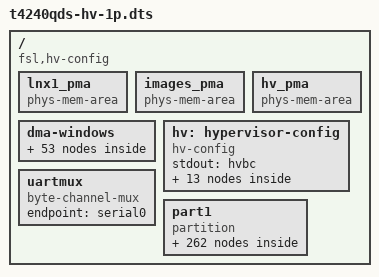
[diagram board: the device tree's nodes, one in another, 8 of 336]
/* Hypervisor Configuration tree containing all hypervisor configuration
 * parameters and partition definition information.
 * (Note -- Please refer to Hypervisor SW Reference Manual
 * (Chapter 5 Configuration) for further details)
 *
 * Copyright 2014 Freescale Semiconductor, Inc.
 */

/dts-v1/;

/ {	// root node

	// The root node of the configuration device tree must contain a
	// compatible property that identifies the device tree as a hypervisor

	compatible = "fsl,hv-config";

	// =====================================================
	// Physical Memory Areas
	// =====================================================
	lnx1_pma: lnx1_pma {
		compatible = "phys-mem-area";
		addr = <0x0 0x00000000>;	// Linux
		size = <0x0 0x40000000>;	// 1GB
	};


	images_pma: images_pma {
		compatible = "phys-mem-area";
		addr = <0x0 0x78000000>;	// Used for boot-from-RAM
		size = <0x0 0x04000000>;	// 64MB
	};

	hv_pma: hv_pma {
		compatible = "phys-mem-area";
		addr = <0x0 0x7f000000>;	// Hypervisor
		size = <0x0 0x01000000>;	// 16MB
	};

	// =====================================================
	// DMA Windows
	// =====================================================
	dma-windows {
		// DMA window for part1_linux
		dw_linux1: dw_linux1 {
			compatible = "dma-window";
			guest-addr = <0 0>;
			size = <0x0 0x80000000>; // 2GB
			subwindow-count = <2>;

			sub-window@0 {
				compatible = "dma-subwindow";
				guest-addr = <0 0>;
				size = <0 0x40000000>; // 1GB
			};

			// ====================================================
			// The window is used for MSIIR translation. The
			// hypervisor sets  a property in the guest device tree
			// (msi-address-64) which indicates the guest physical
			// address of the MSIIR register.
			// This address must be in the next page after the end
			// of DDR as seen by the guest. This is because, Linux
			// is extending the DDR ATMU with one page in order to
			// cover the MSIIR register.
			// ====================================================
			sub-window@1 {		// MSI sub-window
				compatible = "dma-subwindow";
				guest-addr = <0 0x40000000>;
				size = <0 0x1000>; // 4KB
				pcie-msi-subwindow;
			};

		};

		// DMA window for stash_dqrr for qman-portal0
		dw_dqrr_qportal0: window3 {
			compatible = "dma-window";
			guest-addr = <0xf 0xf6000000>;
			size = <0 0x4000>;
		};

		// DMA window for stash_dqrr for qman-portal1
		dw_dqrr_qportal1: window4 {
			compatible = "dma-window";
			guest-addr = <0xf 0xf6004000>;
			size = <0 0x4000>;
		};

		// DMA window for stash_dqrr for qman-portal2
		dw_dqrr_qportal2: window5 {
			compatible = "dma-window";
			guest-addr = <0xf 0xf6008000>;
			size = <0 0x4000>;
		};

		// DMA window for stash_dqrr for qman-portal3
		dw_dqrr_qportal3: window6 {
			compatible = "dma-window";
			guest-addr = <0xf 0xf600c000>;
			size = <0 0x4000>;
		};

		// DMA window for stash_dqrr for qman-portal4
		dw_dqrr_qportal4: window7 {
			compatible = "dma-window";
			guest-addr = <0xf 0xf6010000>;
			size = <0 0x4000>;
		};

		// DMA window for stash_dqrr for qman-portal5
		dw_dqrr_qportal5: window8 {
			compatible = "dma-window";
			guest-addr = <0xf 0xf6014000>;
			size = <0 0x4000>;
		};

		// DMA window for stash_dqrr for qman-portal6
		dw_dqrr_qportal6: window9 {
			compatible = "dma-window";
			guest-addr = <0xf 0xf6018000>;
			size = <0 0x4000>;
		};

		// DMA window for stash_dqrr for qman-portal7
		dw_dqrr_qportal7: window10 {
			compatible = "dma-window";
			guest-addr = <0xf 0xf601c000>;
			size = <0 0x4000>;
		};

		// DMA window for stash_dqrr for qman-portal8
		dw_dqrr_qportal8: window11 {
			compatible = "dma-window";
			guest-addr = <0xf 0xf6020000>;
			size = <0 0x4000>;
		};

		// DMA window for stash_dqrr for qman-portal9
		dw_dqrr_qportal9: window12 {
			compatible = "dma-window";
			guest-addr = <0xf 0xf6024000>;
			size = <0 0x4000>;
		};

		// DMA window for stash_dqrr for qman-portal10
		dw_dqrr_qportal10: window13 {
			compatible = "dma-window";
			guest-addr = <0xf 0xf6028000>;
			size = <0 0x4000>;
		};

		// DMA window for stash_dqrr for qman-portal11
		dw_dqrr_qportal11: window14 {
			compatible = "dma-window";
			guest-addr = <0xf 0xf602c000>;
			size = <0 0x4000>;
		};

		// DMA window for stash_dqrr for qman-portal12
		dw_dqrr_qportal12: window15 {
			compatible = "dma-window";
			guest-addr = <0xf 0xf6030000>;
			size = <0 0x4000>;
		};

		// DMA window for stash_dqrr for qman-portal13
		dw_dqrr_qportal13: window16 {
			compatible = "dma-window";
			guest-addr = <0xf 0xf6034000>;
			size = <0 0x4000>;
		};

		// DMA window for stash_dqrr for qman-portal14
		dw_dqrr_qportal14: window17 {
			compatible = "dma-window";
			guest-addr = <0xf 0xf6038000>;
			size = <0 0x4000>;
		};

		// DMA window for stash_dqrr for qman-portal15
		dw_dqrr_qportal15: window18 {
			compatible = "dma-window";
			guest-addr = <0xf 0xf603c000>;
			size = <0 0x4000>;
		};

		// DMA window for stash_dqrr for qman-portal16
		dw_dqrr_qportal16: window19 {
			compatible = "dma-window";
			guest-addr = <0xf 0xf6040000>;
			size = <0 0x4000>;
		};

		// DMA window for stash_dqrr for qman-portal17
		dw_dqrr_qportal17: window20 {
			compatible = "dma-window";
			guest-addr = <0xf 0xf6044000>;
			size = <0 0x4000>;
		};

		// DMA window for stash_dqrr for qman-portal18
		dw_dqrr_qportal18: window21 {
			compatible = "dma-window";
			guest-addr = <0xf 0xf6048000>;
			size = <0 0x4000>;
		};

		// DMA window for stash_dqrr for qman-portal19
		dw_dqrr_qportal19: window22 {
			compatible = "dma-window";
			guest-addr = <0xf 0xf604c000>;
			size = <0 0x4000>;
		};

		// DMA window for stash_dqrr for qman-portal20
		dw_dqrr_qportal20: window23 {
			compatible = "dma-window";
			guest-addr = <0xf 0xf6050000>;
			size = <0 0x4000>;
		};

		// DMA window for stash_dqrr for qman-portal21
		dw_dqrr_qportal21: window24 {
			compatible = "dma-window";
			guest-addr = <0xf 0xf6054000>;
			size = <0 0x4000>;
		};

		// DMA window for stash_dqrr for qman-portal22
		dw_dqrr_qportal22: window25 {
			compatible = "dma-window";
			guest-addr = <0xf 0xf6058000>;
			size = <0 0x4000>;
		};

		// DMA window for stash_dqrr for qman-portal23
		dw_dqrr_qportal23: window26 {
			compatible = "dma-window";
			guest-addr = <0xf 0xf605c000>;
			size = <0 0x4000>;
		};

		// DMA window for stash_dqrr for qman-portal24
		dw_dqrr_qportal24: window27 {
			compatible = "dma-window";
			guest-addr = <0xf 0xf6060000>;
			size = <0 0x4000>;
		};

		// DMA window for stash_dqrr for qman-portal25
		dw_dqrr_qportal25: window28 {
			compatible = "dma-window";
			guest-addr = <0xf 0xf6064000>;
			size = <0 0x4000>;
		};

		// DMA window for stash_dqrr for qman-portal26
		dw_dqrr_qportal26: window29 {
			compatible = "dma-window";
			guest-addr = <0xf 0xf6068000>;
			size = <0 0x4000>;
		};

		// DMA window for stash_dqrr for qman-portal27
		dw_dqrr_qportal27: window30 {
			compatible = "dma-window";
			guest-addr = <0xf 0xf606c000>;
			size = <0 0x4000>;
		};

		// DMA window for stash_dqrr for qman-portal28
		dw_dqrr_qportal28: window31 {
			compatible = "dma-window";
			guest-addr = <0xf 0xf6070000>;
			size = <0 0x4000>;
		};

		// DMA window for stash_dqrr for qman-portal29
		dw_dqrr_qportal29: window32 {
			compatible = "dma-window";
			guest-addr = <0xf 0xf6074000>;
			size = <0 0x4000>;
		};

		// DMA window for stash_dqrr for qman-portal30
		dw_dqrr_qportal30: window33 {
			compatible = "dma-window";
			guest-addr = <0xf 0xf6078000>;
			size = <0 0x4000>;
		};

		// DMA window for stash_dqrr for qman-portal31
		dw_dqrr_qportal31: window34 {
			compatible = "dma-window";
			guest-addr = <0xf 0xf607c000>;
			size = <0 0x4000>;
		};

		// DMA window for stash_dqrr for qman-portal32
		dw_dqrr_qportal32: window35 {
			compatible = "dma-window";
			guest-addr = <0xf 0xf6080000>;
			size = <0 0x4000>;
		};

		// DMA window for stash_dqrr for qman-portal33
		dw_dqrr_qportal33: window36 {
			compatible = "dma-window";
			guest-addr = <0xf 0xf6084000>;
			size = <0 0x4000>;
		};

		// DMA window for stash_dqrr for qman-portal34
		dw_dqrr_qportal34: window37 {
			compatible = "dma-window";
			guest-addr = <0xf 0xf6088000>;
			size = <0 0x4000>;
		};

		// DMA window for stash_dqrr for qman-portal35
		dw_dqrr_qportal35: window38 {
			compatible = "dma-window";
			guest-addr = <0xf 0xf608c000>;
			size = <0 0x4000>;
		};

		// DMA window for stash_dqrr for qman-portal36
		dw_dqrr_qportal36: window39 {
			compatible = "dma-window";
			guest-addr = <0xf 0xf6090000>;
			size = <0 0x4000>;
		};

		// DMA window for stash_dqrr for qman-portal37
		dw_dqrr_qportal37: window40 {
			compatible = "dma-window";
			guest-addr = <0xf 0xf6094000>;
			size = <0 0x4000>;
		};

		// DMA window for stash_dqrr for qman-portal38
		dw_dqrr_qportal38: window41 {
			compatible = "dma-window";
			guest-addr = <0xf 0xf6098000>;
			size = <0 0x4000>;
		};

		// DMA window for stash_dqrr for qman-portal39
		dw_dqrr_qportal39: window42 {
			compatible = "dma-window";
			guest-addr = <0xf 0xf609c000>;
			size = <0 0x4000>;
		};

		// DMA window for stash_dqrr for qman-portal40
		dw_dqrr_qportal40: window43 {
			compatible = "dma-window";
			guest-addr = <0xf 0xf60a0000>;
			size = <0 0x4000>;
		};

		// DMA window for stash_dqrr for qman-portal41
		dw_dqrr_qportal41: window44 {
			compatible = "dma-window";
			guest-addr = <0xf 0xf60a4000>;
			size = <0 0x4000>;
		};

		// DMA window for stash_dqrr for qman-portal42
		dw_dqrr_qportal42: window45 {
			compatible = "dma-window";
			guest-addr = <0xf 0xf60a8000>;
			size = <0 0x4000>;
		};

		// DMA window for stash_dqrr for qman-portal43
		dw_dqrr_qportal43: window46 {
			compatible = "dma-window";
			guest-addr = <0xf 0xf60ac000>;
			size = <0 0x4000>;
		};

		// DMA window for stash_dqrr for qman-portal44
		dw_dqrr_qportal44: window47 {
			compatible = "dma-window";
			guest-addr = <0xf 0xf60b0000>;
			size = <0 0x4000>;
		};

		// DMA window for stash_dqrr for qman-portal45
		dw_dqrr_qportal45: window48 {
			compatible = "dma-window";
			guest-addr = <0xf 0xf60b4000>;
			size = <0 0x4000>;
		};

		// DMA window for stash_dqrr for qman-portal46
		dw_dqrr_qportal46: window49 {
			compatible = "dma-window";
			guest-addr = <0xf 0xf60b8000>;
			size = <0 0x4000>;
		};

		// DMA window for stash_dqrr for qman-portal47
		dw_dqrr_qportal47: window50 {
			compatible = "dma-window";
			guest-addr = <0xf 0xf60bc000>;
			size = <0 0x4000>;
		};

		// DMA window for stash_dqrr for qman-portal48
		dw_dqrr_qportal48: window51 {
			compatible = "dma-window";
			guest-addr = <0xf 0xf60c0000>;
			size = <0 0x4000>;
		};

		// DMA window for stash_dqrr for qman-portal49
		dw_dqrr_qportal49: window52 {
			compatible = "dma-window";
			guest-addr = <0xf 0xf60c4000>;
			size = <0 0x4000>;
		};
	};

	// =====================================================
	// Hypervisor Config
	// Hypervisor is also configured via the Hypervisor
	// configuration tree. A special node and subtree defines
	// set of global configuration parameters and a number of
	// device nodes assigning I/O devices to the hypervisor
	// =====================================================
	hv: hypervisor-config {
		compatible = "hv-config";

		// phandle to byte-channel used for hypervisor's console
		stdout = <&hvbc>;

		hv-memory {
			compatible = "hv-memory";
			phys-mem = <&hv_pma>;
		};

		hvbc: byte-channel {
			compatible = "byte-channel";
			endpoint = <&uartmux>;
			mux-channel = <0>;
		};

		// Device nodes given below are the physical I/O
		// devices assigned to hypervisor
		corenet-law {
			device = "/soc/corenet-law";
		};

		cpc {
			device = "/soc/l3-cache-controller";
		};

		corenet-cf {
			device = "/soc/corenet-cf";
		};

		guts {
			device = "/soc/global-utilities@e0000";
		};

		rcpm {
			device = "/soc/global-utilities@e2000";
		};

		iommu {
			device = "/soc/iommu";
		};

		mpic {
			device = "/soc/pic@40000";
		};

		serial0: serial0 {
			device = "serial0";
		};

		serial1: serial1 {
			device = "serial1";
		};

		serial2: serial2 {
			device = "serial2";
		};

		serial3: serial3 {
			device = "serial3";
		};
	};

	// =====================================================
	// UART mux
	// This node is referenced by byte-channels that use mux
	// as an endpoint
	// =====================================================
	uartmux: uartmux {
		compatible = "byte-channel-mux";
		endpoint = <&serial0>;
	};

	// =====================================================
	// Partition 1
	// =====================================================
	part1 {
		// Indicates that it is a partition node
		compatible = "partition";
		label = "p1-linux";
		// CPUs #0 to #23 are assigned to this partition
		cpus = <0 24>;
		guest-image = <0xf 0xe8020000 0 0 0 0x700000>;
		linux-rootfs = <0xf 0xe9300000 0 0x01300000 0 0x02800000>;
		dtb-window = <0 0x1000000 0 0x40000>;

		// Temporary until Linux uses enable LIODN hcall
		no-dma-disable;
		direct-guest-tlb-management;
		direct-guest-tlb-miss;
		gpma0 {
			compatible = "guest-phys-mem-area";
			phys-mem = <&lnx1_pma>;
			guest-addr = <0 0>;
		};

		aliases {
			stdout = <&part1_bc0>;
		};

		// =====================================================
		// Devices assigned to the partition - device nodes
		// device node is child of partition node and is used to
		// assign physical I/O devices to partition
		// =====================================================
		part1_bc0: byte-channel@1 {
			compatible = "byte-channel";
			endpoint = <&uartmux>;
			mux-channel = <1>;
		};

		// Bman portals assigned to this partition
		bman-portal@0 {
			device = "/bman-portals/bman-portal@0";
		};

		bman-portal@4000 {
			device = "/bman-portals/bman-portal@4000";
		};

		bman-portal@8000 {
			device = "/bman-portals/bman-portal@8000";
		};

		bman-portal@c000 {
			device = "/bman-portals/bman-portal@c000";
		};

		bman-portal@10000 {
			device = "/bman-portals/bman-portal@10000";
		};

		bman-portal@14000 {
			device = "/bman-portals/bman-portal@14000";
		};

		bman-portal@18000 {
			device = "/bman-portals/bman-portal@18000";
		};

		bman-portal@1c000 {
			device = "/bman-portals/bman-portal@1c000";
		};

		bman-portal@20000 {
			device = "/bman-portals/bman-portal@20000";
		};

		bman-portal@24000 {
			device = "/bman-portals/bman-portal@24000";
		};

		bman-portal@28000 {
			device = "/bman-portals/bman-portal@28000";
		};

		bman-portal@2c000 {
			device = "/bman-portals/bman-portal@2c000";
		};

		bman-portal@30000 {
			device = "/bman-portals/bman-portal@30000";
		};

		bman-portal@34000 {
			device = "/bman-portals/bman-portal@34000";
		};

		bman-portal@38000 {
			device = "/bman-portals/bman-portal@38000";
		};

		bman-portal@3c000 {
			device = "/bman-portals/bman-portal@3c000";
		};

		bman-portal@40000 {
			device = "/bman-portals/bman-portal@40000";
		};

		bman-portal@44000 {
			device = "/bman-portals/bman-portal@44000";
		};

		bman-portal@48000 {
			device = "/bman-portals/bman-portal@48000";
		};

		bman-portal@4c000 {
			device = "/bman-portals/bman-portal@4c000";
		};

		bman-portal@50000 {
			device = "/bman-portals/bman-portal@50000";
		};

		bman-portal@54000 {
			device = "/bman-portals/bman-portal@54000";
		};

		bman-portal@58000 {
			device = "/bman-portals/bman-portal@58000";
		};

		bman-portal@5c000 {
			device = "/bman-portals/bman-portal@5c000";
		};

		bman-portal@60000 {
			device = "/bman-portals/bman-portal@60000";
		};

		bman-portal@64000 {
			device = "/bman-portals/bman-portal@64000";
		};

		bman-portal@68000 {
			device = "/bman-portals/bman-portal@68000";
		};

		bman-portal@6c000 {
			device = "/bman-portals/bman-portal@6c000";
		};

		bman-portal@70000 {
			device = "/bman-portals/bman-portal@70000";
		};

		bman-portal@74000 {
			device = "/bman-portals/bman-portal@74000";
		};

		bman-portal@78000 {
			device = "/bman-portals/bman-portal@78000";
		};

		bman-portal@7c000 {
			device = "/bman-portals/bman-portal@7c000";
		};

		bman-portal@80000 {
			device = "/bman-portals/bman-portal@80000";
		};

		bman-portal@84000 {
			device = "/bman-portals/bman-portal@84000";
		};

		bman-portal@88000 {
			device = "/bman-portals/bman-portal@88000";
		};

		bman-portal@8c000 {
			device = "/bman-portals/bman-portal@8c000";
		};

		bman-portal@90000 {
			device = "/bman-portals/bman-portal@90000";
		};

		bman-portal@94000 {
			device = "/bman-portals/bman-portal@94000";
		};

		bman-portal@98000 {
			device = "/bman-portals/bman-portal@98000";
		};

		bman-portal@9c000 {
			device = "/bman-portals/bman-portal@9c000";
		};

		bman-portal@a0000 {
			device = "/bman-portals/bman-portal@a0000";
		};

		bman-portal@a4000 {
			device = "/bman-portals/bman-portal@a4000";
		};

		bman-portal@a8000 {
			device = "/bman-portals/bman-portal@a8000";
		};

		bman-portal@ac000 {
			device = "/bman-portals/bman-portal@ac000";
		};

		bman-portal@b0000 {
			device = "/bman-portals/bman-portal@b0000";
		};

		bman-portal@b4000 {
			device = "/bman-portals/bman-portal@b4000";
		};

		bman-portal@b8000 {
			device = "/bman-portals/bman-portal@b8000";
		};

		bman-portal@bc000 {
			device = "/bman-portals/bman-portal@bc000";
		};

		bman-portal@c0000 {
			device = "/bman-portals/bman-portal@c0000";
		};

		bman-portal@c4000 {
			device = "/bman-portals/bman-portal@c4000";
		};

		// Bman buffer pools assigned to this partition
		buffer-pool@7 {
			device = "buffer-pool@7";
		};

		buffer-pool@8 {
			device = "buffer-pool@8";
		};

		buffer-pool@9 {
			device = "buffer-pool@9";
		};

		buffer-pool@16 {
			device = "buffer-pool@16";
		};

		buffer-pool@17 {
			device = "buffer-pool@17";
		};

		qman-portal@0 {
			device = "/qman-portals@ff6000000/qman-portal@0";

			stash-mem {
				liodn-index = <1>;
				dma-window = <&dw_linux1>;
				operation-mapping = <0>;
				stash-dest = <3>;
			};

			stash-dqrr {
				liodn-index = <0>;
				dma-window = <&dw_dqrr_qportal0>;
				operation-mapping = <0>;
				stash-dest = <3>;
			};
		};

		qman-portal@4000 {
			device = "/qman-portals@ff6000000/qman-portal@4000";

			stash-mem {
				liodn-index = <1>;
				dma-window = <&dw_linux1>;
				operation-mapping = <0>;
				stash-dest = <3>;
			};

			stash-dqrr {
				liodn-index = <0>;
				dma-window = <&dw_dqrr_qportal1>;
				operation-mapping = <0>;
				stash-dest = <3>;
			};
		};

		qman-portal@8000 {
			device = "/qman-portals@ff6000000/qman-portal@8000";

			stash-mem {
				liodn-index = <1>;
				dma-window = <&dw_linux1>;
				operation-mapping = <0>;
				stash-dest = <3>;
			};

			stash-dqrr {
				liodn-index = <0>;
				dma-window = <&dw_dqrr_qportal2>;
				operation-mapping = <0>;
				stash-dest = <3>;
			};
		};

		qman-portal@c000 {
			device = "/qman-portals@ff6000000/qman-portal@c000";

			stash-mem {
				liodn-index = <1>;
				dma-window = <&dw_linux1>;
				operation-mapping = <0>;
				stash-dest = <3>;
			};

			stash-dqrr {
				liodn-index = <0>;
				dma-window = <&dw_dqrr_qportal3>;
				operation-mapping = <0>;
				stash-dest = <3>;
			};
		};

		qman-portal@10000 {
			device = "/qman-portals@ff6000000/qman-portal@10000";

			stash-mem {
				liodn-index = <1>;
				dma-window = <&dw_linux1>;
				operation-mapping = <0>;
				stash-dest = <3>;
			};

			stash-dqrr {
				liodn-index = <0>;
				dma-window = <&dw_dqrr_qportal4>;
				operation-mapping = <0>;
				stash-dest = <3>;
			};
		};

		qman-portal@14000 {
			device = "/qman-portals@ff6000000/qman-portal@14000";

			stash-mem {
				liodn-index = <1>;
				dma-window = <&dw_linux1>;
				operation-mapping = <0>;
				stash-dest = <3>;
			};

			stash-dqrr {
				liodn-index = <0>;
				dma-window = <&dw_dqrr_qportal5>;
				operation-mapping = <0>;
				stash-dest = <3>;
			};
		};

		qman-portal@18000 {
			device = "/qman-portals@ff6000000/qman-portal@18000";

			stash-mem {
				liodn-index = <1>;
				dma-window = <&dw_linux1>;
				operation-mapping = <0>;
				stash-dest = <3>;
			};

			stash-dqrr {
				liodn-index = <0>;
				dma-window = <&dw_dqrr_qportal6>;
				operation-mapping = <0>;
				stash-dest = <3>;
			};
		};

		qman-portal@1c000 {
			device = "/qman-portals@ff6000000/qman-portal@1c000";

			stash-mem {
				liodn-index = <1>;
				dma-window = <&dw_linux1>;
				operation-mapping = <0>;
				stash-dest = <3>;
			};

			stash-dqrr {
				liodn-index = <0>;
				dma-window = <&dw_dqrr_qportal7>;
				operation-mapping = <0>;
				stash-dest = <3>;
			};
		};

		qman-portal@20000 {
			device = "/qman-portals@ff6000000/qman-portal@20000";

			stash-mem {
				liodn-index = <1>;
				dma-window = <&dw_linux1>;
				operation-mapping = <0>;
				stash-dest = <3>;
			};

			stash-dqrr {
				liodn-index = <0>;
				dma-window = <&dw_dqrr_qportal8>;
				operation-mapping = <0>;
				stash-dest = <3>;
			};
		};

		qman-portal@24000 {
			device = "/qman-portals@ff6000000/qman-portal@24000";

			stash-mem {
				liodn-index = <1>;
				dma-window = <&dw_linux1>;
				operation-mapping = <0>;
				stash-dest = <3>;
			};

			stash-dqrr {
				liodn-index = <0>;
				dma-window = <&dw_dqrr_qportal9>;
				operation-mapping = <0>;
				stash-dest = <3>;
			};
		};

		qman-portal@28000 {
			device = "/qman-portals@ff6000000/qman-portal@28000";

			stash-mem {
				liodn-index = <1>;
				dma-window = <&dw_linux1>;
				operation-mapping = <0>;
				stash-dest = <3>;
			};

			stash-dqrr {
				liodn-index = <0>;
				dma-window = <&dw_dqrr_qportal10>;
				operation-mapping = <0>;
				stash-dest = <3>;
			};
		};

		qman-portal@2c000 {
			device = "/qman-portals@ff6000000/qman-portal@2c000";

			stash-mem {
				liodn-index = <1>;
				dma-window = <&dw_linux1>;
				operation-mapping = <0>;
				stash-dest = <3>;
			};

			stash-dqrr {
				liodn-index = <0>;
				dma-window = <&dw_dqrr_qportal11>;
				operation-mapping = <0>;
				stash-dest = <3>;
			};
		};

		qman-portal@30000 {
			device = "/qman-portals@ff6000000/qman-portal@30000";

			stash-mem {
				liodn-index = <1>;
				dma-window = <&dw_linux1>;
				operation-mapping = <0>;
				stash-dest = <3>;
			};

			stash-dqrr {
				liodn-index = <0>;
				dma-window = <&dw_dqrr_qportal12>;
				operation-mapping = <0>;
				stash-dest = <3>;
			};
		};

		qman-portal@34000 {
			device = "/qman-portals@ff6000000/qman-portal@34000";

			stash-mem {
				liodn-index = <1>;
				dma-window = <&dw_linux1>;
				operation-mapping = <0>;
				stash-dest = <3>;
			};

			stash-dqrr {
				liodn-index = <0>;
				dma-window = <&dw_dqrr_qportal13>;
				operation-mapping = <0>;
				stash-dest = <3>;
			};
		};

		qman-portal@38000 {
			device = "/qman-portals@ff6000000/qman-portal@38000";

			stash-mem {
				liodn-index = <1>;
				dma-window = <&dw_linux1>;
				operation-mapping = <0>;
				stash-dest = <3>;
			};

			stash-dqrr {
				liodn-index = <0>;
				dma-window = <&dw_dqrr_qportal14>;
				operation-mapping = <0>;
				stash-dest = <3>;
			};
		};

		qman-portal@3c000 {
			device = "/qman-portals@ff6000000/qman-portal@3c000";

			stash-mem {
				liodn-index = <1>;
				dma-window = <&dw_linux1>;
				operation-mapping = <0>;
				stash-dest = <3>;
			};

			stash-dqrr {
				liodn-index = <0>;
				dma-window = <&dw_dqrr_qportal15>;
				operation-mapping = <0>;
				stash-dest = <3>;
			};
		};

		qman-portal@40000 {
			device = "/qman-portals@ff6000000/qman-portal@40000";

			stash-mem {
				liodn-index = <1>;
				dma-window = <&dw_linux1>;
				operation-mapping = <0>;
				stash-dest = <3>;
			};

			stash-dqrr {
				liodn-index = <0>;
				dma-window = <&dw_dqrr_qportal16>;
				operation-mapping = <0>;
				stash-dest = <3>;
			};
		};

		qman-portal@44000 {
			device = "/qman-portals@ff6000000/qman-portal@44000";

			stash-mem {
				liodn-index = <1>;
				dma-window = <&dw_linux1>;
				operation-mapping = <0>;
				stash-dest = <3>;
			};

			stash-dqrr {
				liodn-index = <0>;
				dma-window = <&dw_dqrr_qportal17>;
				operation-mapping = <0>;
				stash-dest = <3>;
			};
		};

		qman-portal@48000 {
			device = "/qman-portals@ff6000000/qman-portal@48000";

			stash-mem {
				liodn-index = <1>;
				dma-window = <&dw_linux1>;
				operation-mapping = <0>;
				stash-dest = <3>;
			};

			stash-dqrr {
				liodn-index = <0>;
				dma-window = <&dw_dqrr_qportal18>;
				operation-mapping = <0>;
				stash-dest = <3>;
			};
		};

		qman-portal@4c000 {
			device = "/qman-portals@ff6000000/qman-portal@4c000";

			stash-mem {
				liodn-index = <1>;
				dma-window = <&dw_linux1>;
				operation-mapping = <0>;
				stash-dest = <3>;
			};

			stash-dqrr {
				liodn-index = <0>;
				dma-window = <&dw_dqrr_qportal19>;
				operation-mapping = <0>;
				stash-dest = <3>;
			};
		};

		qman-portal@50000 {
			device = "/qman-portals@ff6000000/qman-portal@50000";

			stash-mem {
				liodn-index = <1>;
				dma-window = <&dw_linux1>;
				operation-mapping = <0>;
				stash-dest = <3>;
			};

			stash-dqrr {
				liodn-index = <0>;
				dma-window = <&dw_dqrr_qportal20>;
				operation-mapping = <0>;
				stash-dest = <3>;
			};
		};

		qman-portal@54000 {
			device = "/qman-portals@ff6000000/qman-portal@54000";

			stash-mem {
				liodn-index = <1>;
				dma-window = <&dw_linux1>;
				operation-mapping = <0>;
				stash-dest = <3>;
			};

			stash-dqrr {
				liodn-index = <0>;
				dma-window = <&dw_dqrr_qportal21>;
				operation-mapping = <0>;
				stash-dest = <3>;
			};
		};

		qman-portal@58000 {
			device = "/qman-portals@ff6000000/qman-portal@58000";

			stash-mem {
				liodn-index = <1>;
				dma-window = <&dw_linux1>;
				operation-mapping = <0>;
				stash-dest = <3>;
			};

			stash-dqrr {
				liodn-index = <0>;
				dma-window = <&dw_dqrr_qportal22>;
				operation-mapping = <0>;
				stash-dest = <3>;
			};
		};

		qman-portal@5c000 {
			device = "/qman-portals@ff6000000/qman-portal@5c000";

			stash-mem {
				liodn-index = <1>;
				dma-window = <&dw_linux1>;
				operation-mapping = <0>;
				stash-dest = <3>;
			};

			stash-dqrr {
				liodn-index = <0>;
				dma-window = <&dw_dqrr_qportal23>;
				operation-mapping = <0>;
				stash-dest = <3>;
			};
		};

		qman-portal@60000 {
			device = "/qman-portals@ff6000000/qman-portal@60000";

			stash-mem {
				liodn-index = <1>;
				dma-window = <&dw_linux1>;
				operation-mapping = <0>;
				stash-dest = <3>;
			};

			stash-dqrr {
				liodn-index = <0>;
				dma-window = <&dw_dqrr_qportal24>;
				operation-mapping = <0>;
				stash-dest = <3>;
			};
		};

		qman-portal@64000 {
			device = "/qman-portals@ff6000000/qman-portal@64000";

			stash-mem {
				liodn-index = <1>;
				dma-window = <&dw_linux1>;
				operation-mapping = <0>;
				stash-dest = <3>;
			};

			stash-dqrr {
				liodn-index = <0>;
				dma-window = <&dw_dqrr_qportal25>;
				operation-mapping = <0>;
				stash-dest = <3>;
			};
		};

		qman-portal@68000 {
			device = "/qman-portals@ff6000000/qman-portal@68000";

			stash-mem {
				liodn-index = <1>;
				dma-window = <&dw_linux1>;
				operation-mapping = <0>;
				stash-dest = <3>;
			};

			stash-dqrr {
				liodn-index = <0>;
				dma-window = <&dw_dqrr_qportal26>;
				operation-mapping = <0>;
				stash-dest = <3>;
			};
		};

		qman-portal@6c000 {
			device = "/qman-portals@ff6000000/qman-portal@6c000";

			stash-mem {
				liodn-index = <1>;
				dma-window = <&dw_linux1>;
				operation-mapping = <0>;
				stash-dest = <3>;
			};

			stash-dqrr {
				liodn-index = <0>;
				dma-window = <&dw_dqrr_qportal27>;
				operation-mapping = <0>;
				stash-dest = <3>;
			};
		};

		qman-portal@70000 {
			device = "/qman-portals@ff6000000/qman-portal@70000";

			stash-mem {
				liodn-index = <1>;
				dma-window = <&dw_linux1>;
				operation-mapping = <0>;
				stash-dest = <3>;
			};

			stash-dqrr {
				liodn-index = <0>;
				dma-window = <&dw_dqrr_qportal28>;
				operation-mapping = <0>;
				stash-dest = <3>;
			};
		};

		qman-portal@74000 {
			device = "/qman-portals@ff6000000/qman-portal@74000";

			stash-mem {
				liodn-index = <1>;
				dma-window = <&dw_linux1>;
				operation-mapping = <0>;
				stash-dest = <3>;
			};

			stash-dqrr {
				liodn-index = <0>;
				dma-window = <&dw_dqrr_qportal29>;
				operation-mapping = <0>;
				stash-dest = <3>;
			};
		};

		qman-portal@78000 {
			device = "/qman-portals@ff6000000/qman-portal@78000";

			stash-mem {
				liodn-index = <1>;
				dma-window = <&dw_linux1>;
				operation-mapping = <0>;
				stash-dest = <3>;
			};

			stash-dqrr {
				liodn-index = <0>;
				dma-window = <&dw_dqrr_qportal30>;
				operation-mapping = <0>;
				stash-dest = <3>;
			};
		};

		qman-portal@7c000 {
			device = "/qman-portals@ff6000000/qman-portal@7c000";

			stash-mem {
				liodn-index = <1>;
				dma-window = <&dw_linux1>;
				operation-mapping = <0>;
				stash-dest = <3>;
			};

			stash-dqrr {
				liodn-index = <0>;
				dma-window = <&dw_dqrr_qportal31>;
				operation-mapping = <0>;
				stash-dest = <3>;
			};
		};

		qman-portal@80000 {
			device = "/qman-portals@ff6000000/qman-portal@80000";

			stash-mem {
				liodn-index = <1>;
				dma-window = <&dw_linux1>;
				operation-mapping = <0>;
				stash-dest = <3>;
			};

			stash-dqrr {
				liodn-index = <0>;
				dma-window = <&dw_dqrr_qportal32>;
				operation-mapping = <0>;
				stash-dest = <3>;
			};
		};

		qman-portal@84000 {
			device = "/qman-portals@ff6000000/qman-portal@84000";

			stash-mem {
				liodn-index = <1>;
				dma-window = <&dw_linux1>;
				operation-mapping = <0>;
				stash-dest = <3>;
			};

			stash-dqrr {
				liodn-index = <0>;
				dma-window = <&dw_dqrr_qportal33>;
				operation-mapping = <0>;
				stash-dest = <3>;
			};
		};

		qman-portal@88000 {
			device = "/qman-portals@ff6000000/qman-portal@88000";

			stash-mem {
				liodn-index = <1>;
				dma-window = <&dw_linux1>;
				operation-mapping = <0>;
				stash-dest = <3>;
			};

			stash-dqrr {
				liodn-index = <0>;
				dma-window = <&dw_dqrr_qportal34>;
				operation-mapping = <0>;
				stash-dest = <3>;
			};
		};

		qman-portal@8c000 {
			device = "/qman-portals@ff6000000/qman-portal@8c000";

			stash-mem {
				liodn-index = <1>;
				dma-window = <&dw_linux1>;
				operation-mapping = <0>;
				stash-dest = <3>;
			};

			stash-dqrr {
				liodn-index = <0>;
				dma-window = <&dw_dqrr_qportal35>;
				operation-mapping = <0>;
				stash-dest = <3>;
			};
		};

		qman-portal@90000 {
			device = "/qman-portals@ff6000000/qman-portal@90000";

			stash-mem {
				liodn-index = <1>;
				dma-window = <&dw_linux1>;
				operation-mapping = <0>;
				stash-dest = <3>;
			};

			stash-dqrr {
				liodn-index = <0>;
				dma-window = <&dw_dqrr_qportal36>;
				operation-mapping = <0>;
				stash-dest = <3>;
			};
		};

		qman-portal@94000 {
			device = "/qman-portals@ff6000000/qman-portal@94000";

			stash-mem {
				liodn-index = <1>;
				dma-window = <&dw_linux1>;
				operation-mapping = <0>;
				stash-dest = <3>;
			};

			stash-dqrr {
				liodn-index = <0>;
				dma-window = <&dw_dqrr_qportal37>;
				operation-mapping = <0>;
				stash-dest = <3>;
			};
		};

		qman-portal@98000 {
			device = "/qman-portals@ff6000000/qman-portal@98000";

			stash-mem {
				liodn-index = <1>;
				dma-window = <&dw_linux1>;
				operation-mapping = <0>;
				stash-dest = <3>;
			};

			stash-dqrr {
				liodn-index = <0>;
				dma-window = <&dw_dqrr_qportal38>;
				operation-mapping = <0>;
				stash-dest = <3>;
			};
		};

		qman-portal@9c000 {
			device = "/qman-portals@ff6000000/qman-portal@9c000";

			stash-mem {
				liodn-index = <1>;
				dma-window = <&dw_linux1>;
				operation-mapping = <0>;
				stash-dest = <3>;
			};

			stash-dqrr {
				liodn-index = <0>;
				dma-window = <&dw_dqrr_qportal39>;
				operation-mapping = <0>;
				stash-dest = <3>;
			};
		};

		qman-portal@a0000 {
			device = "/qman-portals@ff6000000/qman-portal@a0000";

			stash-mem {
				liodn-index = <1>;
				dma-window = <&dw_linux1>;
				operation-mapping = <0>;
				stash-dest = <3>;
			};

			stash-dqrr {
				liodn-index = <0>;
				dma-window = <&dw_dqrr_qportal40>;
				operation-mapping = <0>;
				stash-dest = <3>;
			};
		};

		qman-portal@a4000 {
			device = "/qman-portals@ff6000000/qman-portal@a4000";

			stash-mem {
				liodn-index = <1>;
				dma-window = <&dw_linux1>;
				operation-mapping = <0>;
				stash-dest = <3>;
			};

			stash-dqrr {
				liodn-index = <0>;
				dma-window = <&dw_dqrr_qportal41>;
				operation-mapping = <0>;
				stash-dest = <3>;
			};
		};

		qman-portal@a8000 {
			device = "/qman-portals@ff6000000/qman-portal@a8000";

			stash-mem {
				liodn-index = <1>;
				dma-window = <&dw_linux1>;
				operation-mapping = <0>;
				stash-dest = <3>;
			};

			stash-dqrr {
				liodn-index = <0>;
				dma-window = <&dw_dqrr_qportal42>;
				operation-mapping = <0>;
				stash-dest = <3>;
			};
		};

		qman-portal@ac000 {
			device = "/qman-portals@ff6000000/qman-portal@ac000";

			stash-mem {
				liodn-index = <1>;
				dma-window = <&dw_linux1>;
				operation-mapping = <0>;
				stash-dest = <3>;
			};

			stash-dqrr {
				liodn-index = <0>;
				dma-window = <&dw_dqrr_qportal43>;
				operation-mapping = <0>;
				stash-dest = <3>;
			};
		};

		qman-portal@b0000 {
			device = "/qman-portals@ff6000000/qman-portal@b0000";

			stash-mem {
				liodn-index = <1>;
				dma-window = <&dw_linux1>;
				operation-mapping = <0>;
				stash-dest = <3>;
			};

			stash-dqrr {
				liodn-index = <0>;
				dma-window = <&dw_dqrr_qportal44>;
				operation-mapping = <0>;
				stash-dest = <3>;
			};
		};

		qman-portal@b4000 {
			device = "/qman-portals@ff6000000/qman-portal@b4000";

			stash-mem {
				liodn-index = <1>;
				dma-window = <&dw_linux1>;
				operation-mapping = <0>;
				stash-dest = <3>;
			};

			stash-dqrr {
				liodn-index = <0>;
				dma-window = <&dw_dqrr_qportal45>;
				operation-mapping = <0>;
				stash-dest = <3>;
			};
		};

		qman-portal@b8000 {
			device = "/qman-portals@ff6000000/qman-portal@b8000";

			stash-mem {
				liodn-index = <1>;
				dma-window = <&dw_linux1>;
				operation-mapping = <0>;
				stash-dest = <3>;
			};

			stash-dqrr {
				liodn-index = <0>;
				dma-window = <&dw_dqrr_qportal46>;
				operation-mapping = <0>;
				stash-dest = <3>;
			};
		};

		qman-portal@bc000 {
			device = "/qman-portals@ff6000000/qman-portal@bc000";

			stash-mem {
				liodn-index = <1>;
				dma-window = <&dw_linux1>;
				operation-mapping = <0>;
				stash-dest = <3>;
			};

			stash-dqrr {
				liodn-index = <0>;
				dma-window = <&dw_dqrr_qportal47>;
				operation-mapping = <0>;
				stash-dest = <3>;
			};
		};

		qman-portal@c0000 {
			device = "/qman-portals@ff6000000/qman-portal@c0000";

			stash-mem {
				liodn-index = <1>;
				dma-window = <&dw_linux1>;
				operation-mapping = <0>;
				stash-dest = <3>;
			};

			stash-dqrr {
				liodn-index = <0>;
				dma-window = <&dw_dqrr_qportal48>;
				operation-mapping = <0>;
				stash-dest = <3>;
			};
		};

		qman-portal@c4000 {
			device = "/qman-portals@ff6000000/qman-portal@c4000";

			stash-mem {
				liodn-index = <1>;
				dma-window = <&dw_linux1>;
				operation-mapping = <0>;
				stash-dest = <3>;
			};

			stash-dqrr {
				liodn-index = <0>;
				dma-window = <&dw_dqrr_qportal49>;
				operation-mapping = <0>;
				stash-dest = <3>;
			};
		};

		memory-controller@8000 {
			device = "/soc/memory-controller@8000";
		};

		memory-controller@9000 {
			device = "/soc/memory-controller@9000";
		};

		msi0: msi@41600 {
			device = "/soc@ffe000000/msi@41600";
		};

		msi1: msi@41800 {
			device = "/soc@ffe000000/msi@41800";
		};

		msi2: msi@41a00 {
			device = "/soc@ffe000000/msi@41a00";
		};

		dma0 {
			device = "dma0";
			dma-window = <&dw_linux1>;
		};

		sdhc {
			device = "sdhc";
			dma-window = <&dw_linux1>;
		};

		i2c@118000 {
			device = "/soc/i2c@118000";
		};

		i2c@118100 {
			device = "/soc/i2c@118100";
		};

		flash {
			device = "/localbus";
		};

		spi {
			device = "/soc/spi@110000";
		};

		gpio {
			device = "/soc/gpio";
		};

		pci0 {
			device = "pci0";
			map-ranges;
			dma-window = <&dw_linux1>;
			node-update-phandle {
				fsl,msi = <&msi0>;
			};
		};

		pci1 {
			device = "pci1";
			map-ranges;
			dma-window = <&dw_linux1>;
			node-update-phandle {
				fsl,msi = <&msi1>;
			};
		};

		rapidio {
			device = "rapidio@ffe0c0000";
			map-ranges;
			dma-window = <&dw_linux1>;
		};

		pci2 {
			device = "pci2";
			map-ranges;
			dma-window = <&dw_linux1>;
			node-update-phandle {
				fsl,msi = <&msi2>;
			};
		};

		usb0 {
			device = "usb0";
			dma-window = <&dw_linux1>;
		};

		usb1 {
			device = "usb1";
			dma-window = <&dw_linux1>;
		};

		sata@220000 {
			device = "/soc/sata@220000";
			dma-window = <&dw_linux1>;
		};

		sata@221000 {
			device = "/soc/sata@221000";
			dma-window = <&dw_linux1>;
		};

		crypto {
			device = "/soc/crypto";
			dma-window = <&dw_linux1>;
		};

		pme {
			device = "pme";
			dma-window = <&dw_linux1>;
		};

		dce {
			device = "dce";
			dma-window = <&dw_linux1>;
		};

		rman {
			device = "rman";
			dma-window = <&dw_linux1>;
		};

		qman {
			device = "qman";
			dma-window = <&dw_linux1>;
			operation-mapping = <2>;	// OMI_QMAN_PRIV
			stash-dest = <3>;		// L3/CPC
		};

		bman {
			device = "bman";
			dma-window = <&dw_linux1>;
		};

		fman0 {
			device = "fman0";
			dma-window = <&dw_linux1>;
		};

		fman1 {
			device = "fman1";
			dma-window = <&dw_linux1>;
		};

		// FMAN0 RGMII - ethernet 4 assigned to this partition
		dpa-ethernet@4 {
			device = "/fsl,dpaa/ethernet@4";
		};

		// FMAN0 XAUI -- ethernet 6 assigned to this partition
		dpa-ethernet@6 {
			device = "/fsl,dpaa/ethernet@6";
		};

		// FMAN0 XAUI -- ethernet 7 assigned to this partition
		dpa-ethernet@7 {
			device = "/fsl,dpaa/ethernet@7";
		};

		// FMAN1 RGMII -- ethernet 12 assigned to this partition
		dpa-ethernet@12 {
			device = "/fsl,dpaa/ethernet@12";
		};

		// FMAN1 SGMII -- ethernet 13 assigned to this partition
		dpa-ethernet@13 {
			device = "/fsl,dpaa/ethernet@13";
		};

		// FMAN1 XAUI -- ethernet 14 assigned to this partition
		dpa-ethernet@14 {
			device = "/fsl,dpaa/ethernet@14";
		};

		// FMAN1 XAUI -- ethernet 15 assigned to this partition
		dpa-ethernet@15 {
			device = "/fsl,dpaa/ethernet@15";
		};

		// MAC-less b/w kernel and USDPAA -- assigned to this partition
		dpa-ethernet@16 {
			device = "/fsl,dpaa/ethernet@16";
		};
		portal-devices {
			fman0 {
				device = "fman0";
				dma-window = <&dw_linux1>;
			};

			fman1 {
				device = "fman1";
				dma-window = <&dw_linux1>;
			};

			caam {
				device = "crypto";
				dma-window = <&dw_linux1>;
			};

			pme {
				device = "pme";
				dma-window = <&dw_linux1>;
			};

			rman {
				device = "rman";
				dma-window = <&dw_linux1>;
			};

			dce {
				device = "dce";
				dma-window = <&dw_linux1>;
			};
		};

		node-update {
			chosen {
				bootargs = "usdpaa_mem=64M";
			};
		};

		dpa-fman0-oh@1 {
			device = "/fsl,dpaa/dpa-fman0-oh@1";
		};

		bman-bpids {
			device = "/bman-portals@ff4000000/bman-bpids@0";
		};

		qman-fqids@0 {
			device = "/qman-portals@ff6000000/qman-fqids@0";
		};

		qman-fqids@1 {
			device = "/qman-portals@ff6000000/qman-fqids@1";
		};

		qman-pools {
			device = "/qman-portals@ff6000000/qman-pools@0";
		};

		qman-cgrids {
			device = "/qman-portals@ff6000000/qman-cgrids@0";
		};
	};
};
